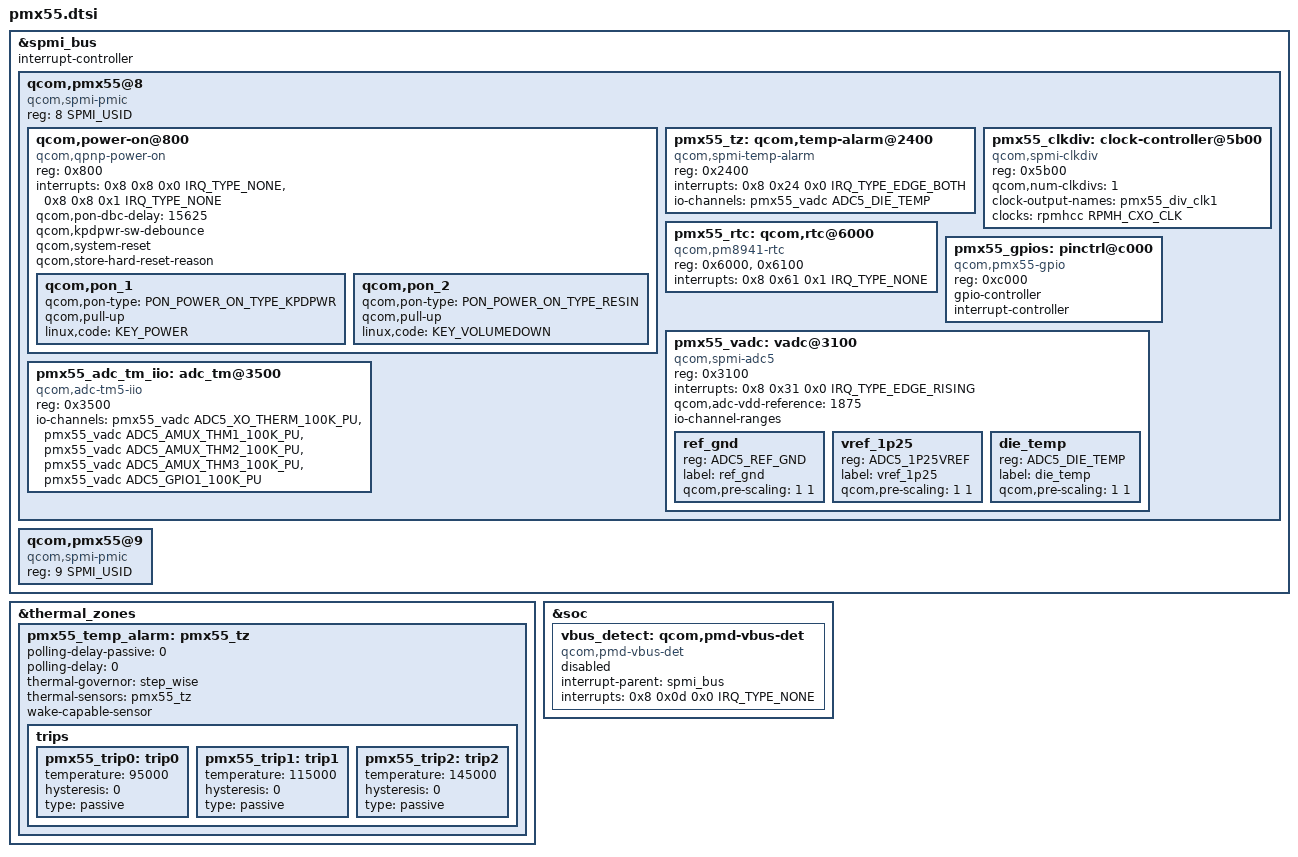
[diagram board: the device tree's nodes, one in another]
#include <dt-bindings/clock/qcom,rpmh.h>
#include <dt-bindings/iio/qcom,spmi-vadc.h>
#include <dt-bindings/input/input.h>
#include <dt-bindings/input/qcom,qpnp-power-on.h>
#include <dt-bindings/interrupt-controller/irq.h>
#include <dt-bindings/spmi/spmi.h>

&spmi_bus {
	#address-cells = <2>;
	#size-cells = <0>;
	interrupt-controller;
	#interrupt-cells = <4>;

	qcom,pmx55@8 {
		compatible = "qcom,spmi-pmic";
		reg = <8 SPMI_USID>;
		#address-cells = <1>;
		#size-cells = <0>;

		qcom,power-on@800 {
			compatible = "qcom,qpnp-power-on";
			reg = <0x800>;
			interrupts = <0x8 0x8 0x0 IRQ_TYPE_NONE>,
				     <0x8 0x8 0x1 IRQ_TYPE_NONE>;
			interrupt-names = "kpdpwr", "resin";
			qcom,pon-dbc-delay = <15625>;
			qcom,kpdpwr-sw-debounce;
			qcom,system-reset;
			qcom,store-hard-reset-reason;

			qcom,pon_1 {
				qcom,pon-type = <PON_POWER_ON_TYPE_KPDPWR>;
				qcom,pull-up;
				linux,code = <KEY_POWER>;
			};

			qcom,pon_2 {
				qcom,pon-type = <PON_POWER_ON_TYPE_RESIN>;
				qcom,pull-up;
				linux,code = <KEY_VOLUMEDOWN>;
			};
		};

		pmx55_tz: qcom,temp-alarm@2400 {
			compatible = "qcom,spmi-temp-alarm";
			reg = <0x2400>;
			interrupts = <0x8 0x24 0x0 IRQ_TYPE_EDGE_BOTH>;
			io-channels = <&pmx55_vadc ADC5_DIE_TEMP>;
			io-channel-names = "thermal";
			#thermal-sensor-cells = <0>;
		};

		pmx55_clkdiv: clock-controller@5b00 {
			compatible = "qcom,spmi-clkdiv";
			reg = <0x5b00>;
			#clock-cells = <1>;
			qcom,num-clkdivs = <1>;
			clock-output-names = "pmx55_div_clk1";
			clocks = <&rpmhcc RPMH_CXO_CLK>;
			clock-names = "xo";
		};

		pmx55_rtc: qcom,rtc@6000 {
			compatible = "qcom,pm8941-rtc";
			reg = <0x6000>, <0x6100>;
			reg-names = "rtc", "alarm";
			interrupts = <0x8 0x61 0x1 IRQ_TYPE_NONE>;
		};

		pmx55_gpios: pinctrl@c000 {
			compatible = "qcom,pmx55-gpio";
			reg = <0xc000>;
			gpio-controller;
			#gpio-cells = <2>;
			interrupt-controller;
			#interrupt-cells = <2>;
		};

		pmx55_vadc: vadc@3100 {
			compatible = "qcom,spmi-adc5";
			reg = <0x3100>;
			#address-cells = <1>;
			#size-cells = <0>;
			interrupts = <0x8 0x31 0x0 IRQ_TYPE_EDGE_RISING>;
			interrupt-names = "eoc-int-en-set";
			qcom,adc-vdd-reference = <1875>;
			#io-channel-cells = <1>;
			io-channel-ranges;

			/* Channel node */
			ref_gnd {
				reg = <ADC5_REF_GND>;
				label = "ref_gnd";
				qcom,pre-scaling = <1 1>;
			};

			vref_1p25 {
				reg = <ADC5_1P25VREF>;
				label = "vref_1p25";
				qcom,pre-scaling = <1 1>;
			};

			die_temp {
				reg = <ADC5_DIE_TEMP>;
				label = "die_temp";
				qcom,pre-scaling = <1 1>;
			};
		};

		pmx55_adc_tm_iio: adc_tm@3500 {
			compatible = "qcom,adc-tm5-iio";
			reg = <0x3500>;
			#address-cells = <1>;
			#size-cells = <0>;
			#thermal-sensor-cells = <1>;
			io-channels = <&pmx55_vadc ADC5_XO_THERM_100K_PU>,
					<&pmx55_vadc ADC5_AMUX_THM1_100K_PU>,
					<&pmx55_vadc ADC5_AMUX_THM2_100K_PU>,
					<&pmx55_vadc ADC5_AMUX_THM3_100K_PU>,
					<&pmx55_vadc ADC5_GPIO1_100K_PU>;
		};
	};

	qcom,pmx55@9 {
		compatible ="qcom,spmi-pmic";
		reg = <9 SPMI_USID>;
		#address-cells = <1>;
		#size-cells = <0>;
	};
};

&thermal_zones {
	pmx55_temp_alarm: pmx55_tz {
		polling-delay-passive = <0>;
		polling-delay = <0>;
		thermal-governor = "step_wise";
		thermal-sensors = <&pmx55_tz>;
		wake-capable-sensor;

		trips {
			pmx55_trip0: trip0 {
				temperature = <95000>;
				hysteresis = <0>;
				type = "passive";
			};

			pmx55_trip1: trip1 {
				temperature = <115000>;
				hysteresis = <0>;
				type = "passive";
			};

			pmx55_trip2: trip2 {
				temperature = <145000>;
				hysteresis = <0>;
				type = "passive";
			};
		};
	};
};

&soc {
	vbus_detect: qcom,pmd-vbus-det {
		compatible = "qcom,pmd-vbus-det";
		interrupt-parent = <&spmi_bus>;
		interrupts = <0x8 0x0d 0x0 IRQ_TYPE_NONE>;
		interrupt-names = "usb_vbus";
		status = "disabled";
	};
};
